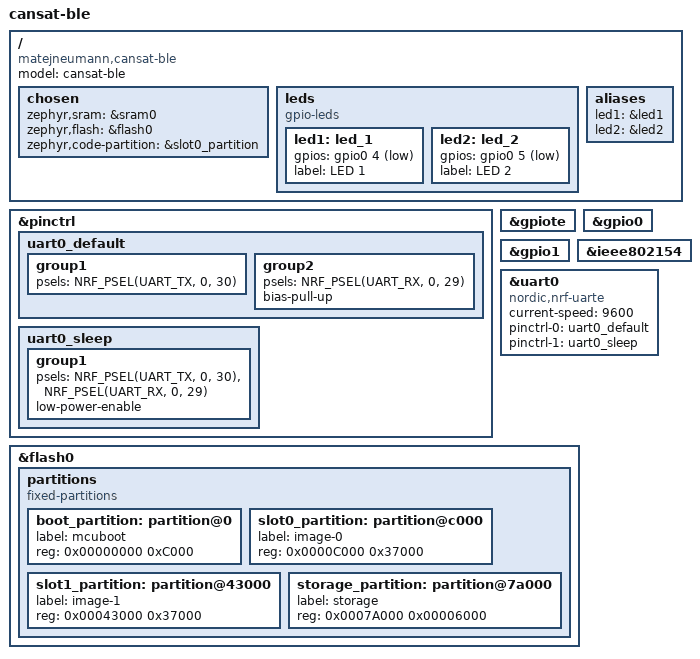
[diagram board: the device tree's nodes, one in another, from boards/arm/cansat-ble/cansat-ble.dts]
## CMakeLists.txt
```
cmake_minimum_required(VERSION 3.20.0)

find_package(Zephyr REQUIRED HINTS $ENV{ZEPHYR_BASE})
project(cansat-ble LANGUAGES C)

# Fetch all component source files
file(GLOB_RECURSE COMPONENT_SOURCES src/components/*.c)

target_sources(app PRIVATE
        src/main.c
        ${COMPONENT_SOURCES} # Include all component source files
)

# Include all component header files
target_include_directories(app PRIVATE src/components)
```

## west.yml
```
manifest:
  remotes:
    - name: nrfconnect
      url-base: https://github.com/nrfconnect
  projects:
    - name: nrf
      repo-path: sdk-nrf
      remote: nrfconnect
      revision: v2.5.0
      import: true
  self:
    path: app
```

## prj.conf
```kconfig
# Bluetooth configuration
CONFIG_BT=y
CONFIG_BT_DEVICE_NAME="BugSat"
CONFIG_BT_LL_SW_SPLIT=y
CONFIG_BT_PERIPHERAL=y
CONFIG_BT_USER_DATA_LEN_UPDATE=y
CONFIG_BT_CTLR_DATA_LENGTH_MAX=251
CONFIG_BT_BUF_ACL_RX_SIZE=251
CONFIG_BT_BUF_ACL_TX_SIZE=251
CONFIG_BT_L2CAP_TX_MTU=128
CONFIG_BT_MAX_CONN=16

# BLE Device information service
CONFIG_BT_DIS=y
CONFIG_BT_DIS_MODEL="BugSat"
CONFIG_BT_DIS_MANUF="DELTA - Matěj Neumann"
CONFIG_BT_DIS_HW_REV=y
CONFIG_BT_DIS_HW_REV_STR="0.2"
CONFIG_BT_DIS_FW_REV=y
CONFIG_BT_DIS_FW_REV_STR="Q1 2024"

# Stack size configuration
# CONFIG_MPSL_WORK_STACK_SIZE=4096
# CONFIG_MAIN_STACK_SIZE=4096

# Logging configuration
CONFIG_LOG=y

# GPIO configuration
CONFIG_GPIO=y

# UART
CONFIG_SERIAL=y
CONFIG_UART_ASYNC_API=y
CONFIG_UART_0_NRF_HW_ASYNC=y
CONFIG_UART_0_NRF_HW_ASYNC_TIMER=3
CONFIG_UART_LINE_CTRL=y

# Power Management
#CONFIG_PM=y
#CONFIG_PM_DEVICE=y
```

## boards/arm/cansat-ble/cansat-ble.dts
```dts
/dts-v1/;
#include <nordic/nrf52833_qdaa.dtsi>

/ {
	model = "cansat-ble";
	compatible = "matejneumann,cansat-ble";
    chosen {
        zephyr,sram = &sram0;
        zephyr,flash = &flash0;
        zephyr,code-partition = &slot0_partition;
    };

    leds {
        compatible = "gpio-leds";
        status = "okay";
        led1: led_1 {
            gpios = <&gpio0 4 GPIO_ACTIVE_LOW>;
            label = "LED 1";
        };
        led2: led_2 {
            gpios = <&gpio0 5 GPIO_ACTIVE_LOW>;
            label = "LED 2";
        };
    };

    aliases {
        led1 = &led1;
        led2 = &led2;
//        watchdog0 = &wdt0;
    };

};

&pinctrl {
    uart0_default: uart0_default {
        group1 {
            psels = <NRF_PSEL(UART_TX, 0, 30)>;
//                    <NRF_PSEL(UART_RTS, 0, 2)>;
        };
        group2 {
            psels = <NRF_PSEL(UART_RX, 0, 29)>;
//                    <NRF_PSEL(UART_CTS, 0, 28)>;
                    bias-pull-up;
        };
    };

    uart0_sleep: uart0_sleep {
        group1 {
            psels = <NRF_PSEL(UART_TX, 0, 30)>,
                    <NRF_PSEL(UART_RX, 0, 29)>;
//                    <NRF_PSEL(UART_RTS, 0, 2)>,
//                    <NRF_PSEL(UART_CTS, 0, 28)>;
                    low-power-enable;
        };
    };
};

&gpiote {
    status = "okay";
};

&gpio0 {
    status = "okay";
};

&gpio1 {
    status = "okay";
};

&ieee802154 {
    status = "okay";
};

&uart0 {
    compatible = "nordic,nrf-uarte";
    status = "okay";
//    interrupts = <2 NRF_DEFAULT_IRQ_PRIORITY>;
    current-speed = <9600>;
    pinctrl-0 = <&uart0_default>;
    pinctrl-1 = <&uart0_sleep>;
    pinctrl-names = "default", "sleep";
};


&flash0 {
    partitions {
        compatible = "fixed-partitions";
        #address-cells = <1>;
        #size-cells = <1>;

        boot_partition: partition@0 {
            label = "mcuboot";
            reg = <0x00000000 0xC000>;
        };
        slot0_partition: partition@c000 {
            label = "image-0";
            reg = <0x0000C000 0x37000>;
        };
        slot1_partition: partition@43000 {
            label = "image-1";
            reg = <0x00043000 0x37000>;
        };
        storage_partition: partition@7a000 {
            label = "storage";
            reg = <0x0007A000 0x00006000>;
        };
    };
};
```

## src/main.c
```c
#include <zephyr/kernel.h>
#include <zephyr/sys/printk.h>
#include <zephyr/logging/log.h>
#include <zephyr/device.h>
#include <zephyr/devicetree.h>
#include <zephyr/drivers/gpio.h>
#include <hal/nrf_gpio.h>

#include "components/bluetooth/bluetooth_core.h"
#include "uart/uart_stm.h"

LOG_MODULE_REGISTER(o_invader_main, LOG_LEVEL_DBG);

#define LED_1 NRF_GPIO_PIN_MAP(0,5)
#define LED_2 NRF_GPIO_PIN_MAP(0,4)

#define SLEEP_TIME_MS 1000

int main(void)
{
//    NRF_TIMER1->BITMODE = TIMER_BITMODE_BITMODE_32Bit << TIMER_BITMODE_BITMODE_Pos;
//    NRF_TIMER1->TASKS_CLEAR = 1;
//    NRF_CLOCK->EVENTS_HFCLKSTARTED = 0;
//    NRF_TIMER1->TASKS_START = 1;
//    NRF_CLOCK->TASKS_HFCLKSTART = 1;
//    int counter = 1000000;
//    while(NRF_CLOCK->EVENTS_HFCLKSTARTED == 0 && counter-- > 0);
////    while(NRF_CLOCK->EVENTS_HFCLKSTARTED == 0);
//    NRF_TIMER1->TASKS_CAPTURE[0] = 1;
//
//    printk("HF Clock has started. Startup time: %d uS\n", NRF_TIMER1->CC[0]);
//    printk("All up and running!\n");
//
//
//
    LOG_INF("Starting up...\n");
    bt_core_initialize();

    nrf_gpio_cfg_output(LED_1);
    nrf_gpio_cfg_output(LED_2);

    nrf_gpio_pin_set(LED_1);
    nrf_gpio_pin_set(LED_2);

    uart_stm_init();

    LOG_INF("All up and running!\n");


    while(1) {
//        nrf_gpio_pin_toggle(LED_1);
//        nrf_gpio_pin_toggle(LED_2);
////        LOG_INF("TOGGLED\n");
        k_sleep(K_MSEC(SLEEP_TIME_MS));
    }

}
```
